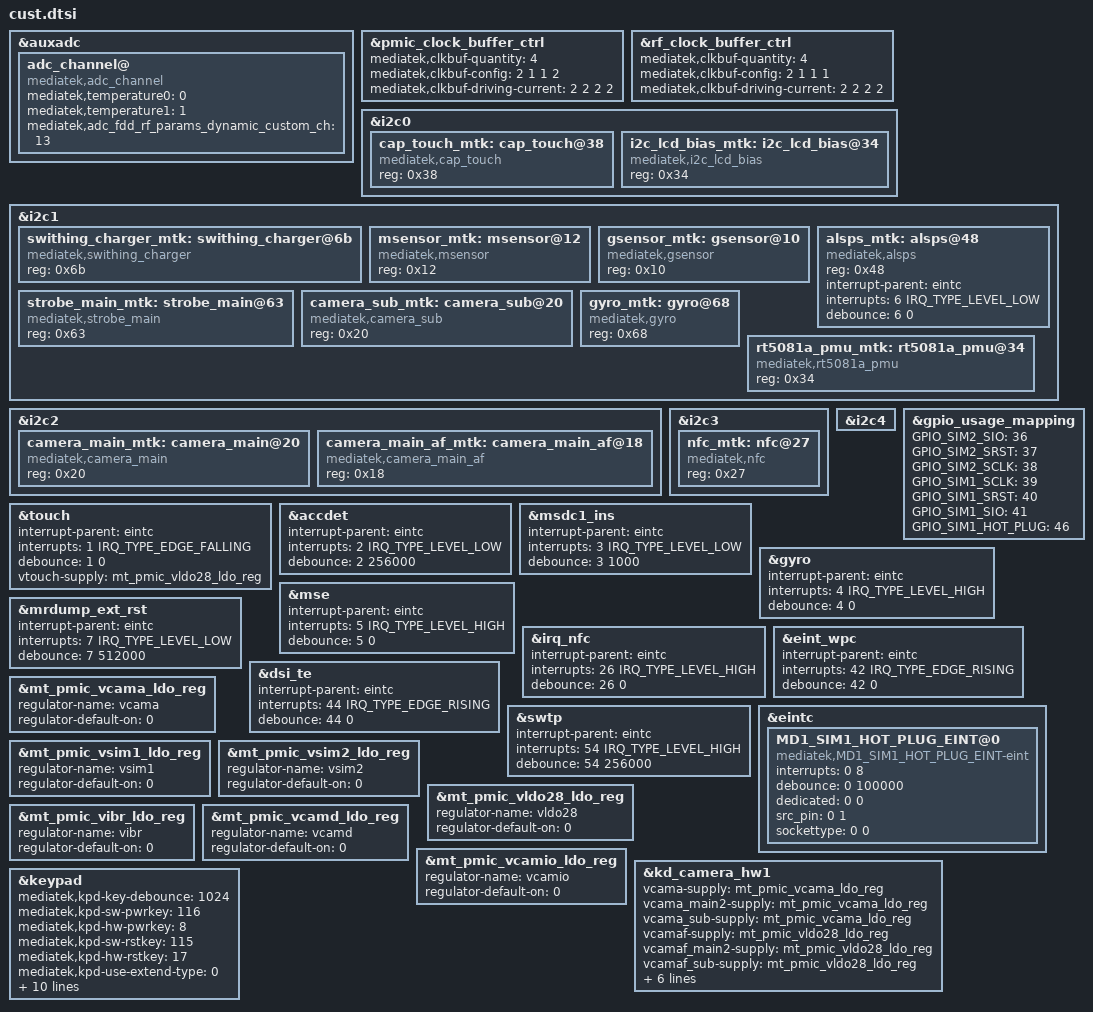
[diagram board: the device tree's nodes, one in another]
/*
 * Generated by MTK SP DrvGen Version: 3.5.160809 for MT6750S.
 * 2025-05-06 16:58:24
 * Do Not Modify The File.
 * Copyright Mediatek Inc. (c) 2016.
*/

/*************************
 * ADC DTSI File
*************************/

&auxadc {
	adc_channel@ {
		compatible = "mediatek,adc_channel";
		mediatek,temperature0 = <0>;
		mediatek,temperature1 = <1>;
		mediatek,adc_fdd_rf_params_dynamic_custom_ch = <13>;
		status = "okay";
	};
};


/*************************
 * CLK_BUF DTSI File
*************************/

&pmic_clock_buffer_ctrl {
	mediatek,clkbuf-quantity = <4>;
	mediatek,clkbuf-config = <2 1 1 2>;
	mediatek,clkbuf-driving-current = <2 2 2 2>;
	status = "okay";
};

&rf_clock_buffer_ctrl {
	mediatek,clkbuf-quantity = <4>;
	mediatek,clkbuf-config = <2 1 1 1>;
	mediatek,clkbuf-driving-current = <2 2 2 2 >;
	status = "okay";
};


/*************************
 * I2C DTSI File
*************************/

&i2c0 {
	#address-cells = <1>;
	#size-cells = <0>;
	cap_touch_mtk:cap_touch@38 {
		compatible = "mediatek,cap_touch";
		reg = <0x38>;
		status = "okay";
	};

	i2c_lcd_bias_mtk:i2c_lcd_bias@34 {
		compatible = "mediatek,i2c_lcd_bias";
		reg = <0x34>;
		status = "okay";
	};

};

&i2c1 {
	#address-cells = <1>;
	#size-cells = <0>;
	swithing_charger_mtk:swithing_charger@6b {
		compatible = "mediatek,swithing_charger";
		reg = <0x6b>;
		status = "okay";
	};

	msensor_mtk:msensor@12 {
		compatible = "mediatek,msensor";
		reg = <0x12>;
		status = "okay";
	};

	gsensor_mtk:gsensor@10 {
		compatible = "mediatek,gsensor";
		reg = <0x10>;
		status = "okay";
	};

	alsps_mtk:alsps@48 {
		compatible = "mediatek,alsps";
		reg = <0x48>;
		status = "okay";
	};

	strobe_main_mtk:strobe_main@63 {
		compatible = "mediatek,strobe_main";
		reg = <0x63>;
		status = "okay";
	};

	camera_sub_mtk:camera_sub@20 {
		compatible = "mediatek,camera_sub";
		reg = <0x20>;
		status = "okay";
	};

	gyro_mtk:gyro@68 {
		compatible = "mediatek,gyro";
		reg = <0x68>;
		status = "okay";
	};

	rt5081a_pmu_mtk:rt5081a_pmu@34 {
		compatible = "mediatek,rt5081a_pmu";
		reg = <0x34>;
		status = "okay";
	};

};

&i2c2 {
	#address-cells = <1>;
	#size-cells = <0>;
	camera_main_mtk:camera_main@20 {
		compatible = "mediatek,camera_main";
		reg = <0x20>;
		status = "okay";
	};

	camera_main_af_mtk:camera_main_af@18 {
		compatible = "mediatek,camera_main_af";
		reg = <0x18>;
		status = "okay";
	};

};

&i2c3 {
	#address-cells = <1>;
	#size-cells = <0>;
	nfc_mtk:nfc@27 {
		compatible = "mediatek,nfc";
		reg = <0x27>;
		status = "okay";
	};

};

&i2c4 {
	#address-cells = <1>;
	#size-cells = <0>;
};



/*************************
 * GPIO DTSI File
*************************/

&gpio_usage_mapping {
	GPIO_SIM2_SIO = <36>;
	GPIO_SIM2_SRST = <37>;
	GPIO_SIM2_SCLK = <38>;
	GPIO_SIM1_SCLK = <39>;
	GPIO_SIM1_SRST = <40>;
	GPIO_SIM1_SIO = <41>;
	GPIO_SIM1_HOT_PLUG = <46>;
};


/*************************
 * EINT DTSI File
*************************/

#include <dt-bindings/interrupt-controller/irq.h>
#include <dt-bindings/interrupt-controller/arm-gic.h>

&touch {
	interrupt-parent = <&eintc>;
	interrupts = <1 IRQ_TYPE_EDGE_FALLING>;
	debounce = <1 0>;
	status = "okay";
};

&accdet {
	interrupt-parent = <&eintc>;
	interrupts = <2 IRQ_TYPE_LEVEL_LOW>;
	debounce = <2 256000>;
	status = "okay";
};

&msdc1_ins {
	interrupt-parent = <&eintc>;
	interrupts = <3 IRQ_TYPE_LEVEL_LOW>;
	debounce = <3 1000>;
	status = "okay";
};

&gyro {
	interrupt-parent = <&eintc>;
	interrupts = <4 IRQ_TYPE_LEVEL_HIGH>;
	debounce = <4 0>;
	status = "okay";
};

&mse {
	interrupt-parent = <&eintc>;
	interrupts = <5 IRQ_TYPE_LEVEL_HIGH>;
	debounce = <5 0>;
	status = "okay";
};

&alsps_mtk {
	interrupt-parent = <&eintc>;
	interrupts = <6 IRQ_TYPE_LEVEL_LOW>;
	debounce = <6 0>;
	status = "okay";
};

&mrdump_ext_rst {
	interrupt-parent = <&eintc>;
	interrupts = <7 IRQ_TYPE_LEVEL_LOW>;
	debounce = <7 512000>;
	status = "okay";
};

&irq_nfc {
	interrupt-parent = <&eintc>;
	interrupts = <26 IRQ_TYPE_LEVEL_HIGH>;
	debounce = <26 0>;
	status = "okay";
};

&eint_wpc {
	interrupt-parent = <&eintc>;
	interrupts = <42 IRQ_TYPE_EDGE_RISING>;
	debounce = <42 0>;
	status = "okay";
};

&dsi_te {
	interrupt-parent = <&eintc>;
	interrupts = <44 IRQ_TYPE_EDGE_RISING>;
	debounce = <44 0>;
	status = "okay";
};

&swtp {
	interrupt-parent = <&eintc>;
	interrupts = <54 IRQ_TYPE_LEVEL_HIGH>;
	debounce = <54 256000>;
	status = "okay";
};



/*************************
 * MD1_EINT DTSI File
*************************/

&eintc {
	MD1_SIM1_HOT_PLUG_EINT@0 {
		compatible = "mediatek,MD1_SIM1_HOT_PLUG_EINT-eint";
		interrupts = <0 8>;
		debounce = <0 100000>;
		dedicated = <0 0>;
		src_pin = <0 1>;
		sockettype = <0 0>;
		status = "okay";
	};

};


/*************************
 * PMIC DTSI File
*************************/

&mt_pmic_vcama_ldo_reg {
	regulator-name = "vcama";
	regulator-default-on = <0>; /* 0:skip, 1: off, 2:on */
	status = "okay";
};
&mt_pmic_vsim1_ldo_reg {
	regulator-name = "vsim1";
	regulator-default-on = <0>; /* 0:skip, 1: off, 2:on */
	status = "okay";
};
&mt_pmic_vsim2_ldo_reg {
	regulator-name = "vsim2";
	regulator-default-on = <0>; /* 0:skip, 1: off, 2:on */
	status = "okay";
};
&mt_pmic_vldo28_ldo_reg {
	regulator-name = "vldo28";
	regulator-default-on = <0>; /* 0:skip, 1: off, 2:on */
	status = "okay";
};
&mt_pmic_vibr_ldo_reg {
	regulator-name = "vibr";
	regulator-default-on = <0>; /* 0:skip, 1: off, 2:on */
	status = "okay";
};
&mt_pmic_vcamd_ldo_reg {
	regulator-name = "vcamd";
	regulator-default-on = <0>; /* 0:skip, 1: off, 2:on */
	status = "okay";
};
&mt_pmic_vcamio_ldo_reg {
	regulator-name = "vcamio";
	regulator-default-on = <0>; /* 0:skip, 1: off, 2:on */
	status = "okay";
};

&kd_camera_hw1 {
	vcama-supply = <&mt_pmic_vcama_ldo_reg>;
	vcama_main2-supply = <&mt_pmic_vcama_ldo_reg>;
	vcama_sub-supply = <&mt_pmic_vcama_ldo_reg>;
	vcamaf-supply = <&mt_pmic_vldo28_ldo_reg>;
	vcamaf_main2-supply = <&mt_pmic_vldo28_ldo_reg>;
	vcamaf_sub-supply = <&mt_pmic_vldo28_ldo_reg>;
	vcamd-supply = <&mt_pmic_vcamd_ldo_reg>;
	vcamd_main2-supply = <&mt_pmic_vcamd_ldo_reg>;
	vcamd_sub-supply = <&mt_pmic_vcamd_ldo_reg>;
	vcamio-supply = <&mt_pmic_vcamio_ldo_reg>;
	vcamio_main2-supply = <&mt_pmic_vcamio_ldo_reg>;
	vcamio_sub-supply = <&mt_pmic_vcamio_ldo_reg>;
	status = "okay";
};

&touch {
	vtouch-supply = <&mt_pmic_vldo28_ldo_reg>;
	status = "okay";
};


/*************************
 * POWER DTSI File
*************************/



/*************************
 * KPD DTSI File
*************************/

&keypad {
	mediatek,kpd-key-debounce = <1024>;
	mediatek,kpd-sw-pwrkey = <116>;
	mediatek,kpd-hw-pwrkey = <8>;
	mediatek,kpd-sw-rstkey  = <115>;
	mediatek,kpd-hw-rstkey = <17>;
	mediatek,kpd-use-extend-type = <0>;
	/*HW Keycode [0~71] -> Linux Keycode*/
	mediatek,kpd-hw-map-num = <72>;
	mediatek,kpd-hw-init-map = <114 0 0 0 0 0 0 0 0 0 0 0 0 0 0 0 0 0 0 0 0 0 0 0 0 0 0 0 0 0 0 0 0 0 0 0 0 0 0 0 0 0 0 0 0 0 0 0 0 0 0 0 0 0 0 0 0 0 0 0 0 0 0 0 0 0 0 0 0 0 0 0 >;
	mediatek,kpd-pwrkey-eint-gpio = <0>;
	mediatek,kpd-pwkey-gpio-din  = <0>;
	mediatek,kpd-hw-dl-key0 = <17>;
	mediatek,kpd-hw-dl-key1 = <0>;
	mediatek,kpd-hw-dl-key2 = <8>;
	mediatek,kpd-hw-recovery-key = <17>;
	mediatek,kpd-hw-factory-key = <0>;
	status = "okay";
};


